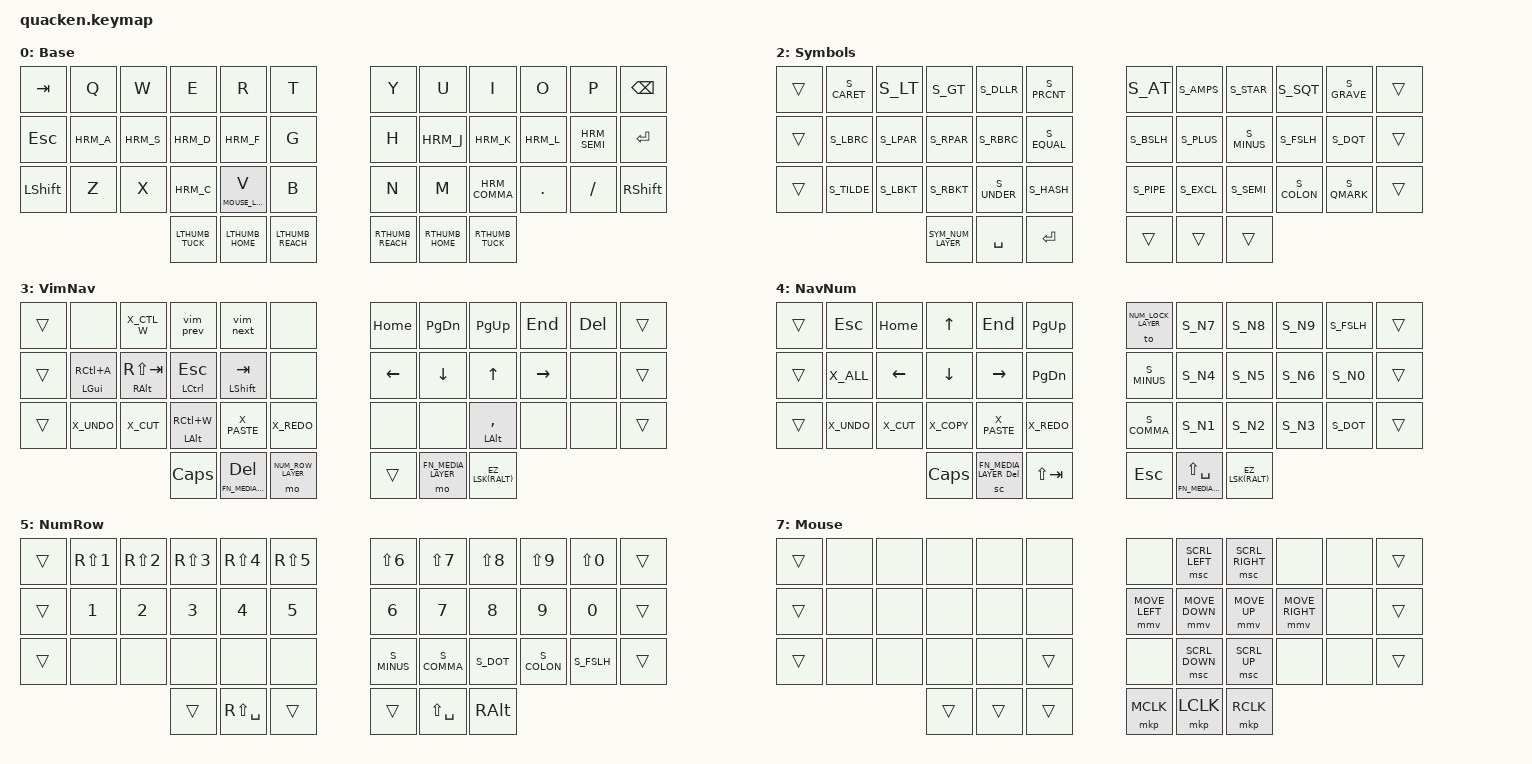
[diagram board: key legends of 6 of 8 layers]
// Selenium keymap:
// https://github.com/OneDeadKey/selenium

#ifndef CI_IGNORE_USER_SETTINGS
  #include "settings.h"   // user settings, ignored by CI tests
#endif

#include "aliases.h"      // symbols, actions, non-ASCII chars
#include "mappings.dtsi"  // key mapping helpers and macros
#include "hold_taps.dtsi" // thumb keys and homerow mods
#undef REACH_TAP
#define REACH_TAP TAB

/ {
  keymap {
    compatible = "zmk,keymap";

    // 0. Base layer -- keep the QWERTY key codes to use your OS keyboard layout
    //               -- the Space Cadet layer-tap on the right can be replaced by an AltGr/Enter mod-tap
    //               -- adjust the homerow mods with the #define statements above
    base_layer: base_layer {
      display-name = "Base";
      bindings = <
        &kp TAB    &kp Q  &kp W  &kp E  &kp R  &kp T        &kp Y  &kp U  &kp I     &kp O   &kp P      &kp BACKSPACE
        &kp ESCAPE HRM_A  HRM_S  HRM_D  HRM_F  &kp G        &kp H  HRM_J  HRM_K     HRM_L   HRM_SEMI   &kp ENTER
        &kp LSHIFT &kp Z  &kp X  HRM_C  &lt MOUSE_LAYER V  &kp B        &kp N  &kp M  HRM_COMMA &kp DOT &kp FSLH   &kp RSHIFT
                LTHUMB_TUCK  LTHUMB_HOME  LTHUMB_REACH    RTHUMB_REACH  RTHUMB_HOME  RTHUMB_TUCK
      >;
    };

    // 1. NumLock layer -- NavNum layer that stays on until deactivated without holding key
    num_lock_layer: num_lock_layer {
      display-name = "NumLock";
      bindings = <
        &trans  &kp ESC  &kp HOME &kp UP   &kp END   &kp PG_UP    &to BASE_LAYER S_N7  S_N8  S_N9  S_FSLH  &trans
        &trans  S_EQUAL  &kp LEFT &kp DOWN &kp RIGHT &kp PG_DN    S_MINUS        S_N4  S_N5  S_N6  S_N0    &trans
        &trans  S_MONEY  S_COLON  S_STAR   S_PLUS    S_PRCNT      S_COMMA        S_N1  S_N2  S_N3  S_DOT   &trans
                &trans  &sc NAV_NUM_LAYER BACKSPACE  &kp (TAB)    &trans  &lt NAV_NUM_LAYER LS(SPACE)  &EZ_SL(SYMBOLS_LAYER)
      >;
    };

    // 2. Symbols layer -- with Ergo-L, basically just an AltGr layer with custom thumb keys
    //                  -- can be redefined for non-AltGr layouts such as QWERTY-ANSI
    symbols_layer: symbols_layer {
      display-name = "Symbols";
      bindings = <
        &trans  S_CARET S_LT    S_GT    S_DLLR  S_PRCNT       S_AT    S_AMPS  S_STAR  S_SQT   S_GRAVE  &trans
        &trans  S_LBRC  S_LPAR  S_RPAR  S_RBRC  S_EQUAL       S_BSLH  S_PLUS  S_MINUS S_FSLH  S_DQT    &trans
        &trans  S_TILDE S_LBKT  S_RBKT  S_UNDER S_HASH        S_PIPE  S_EXCL  S_SEMI  S_COLON S_QMARK  &trans
                    SYM_NUM_LAYER  &kp SPACE  &kp ENTER       &trans  &trans  &trans
      >;
    };

    // 3. VimNav layer -- HJKL arrow cluster on the right hand
    //                 -- best used along with the NumRow layer
    //                 -- keyboard shortcuts on the left hand are adjusted to the OS layout (Ergo-L here)
    vim_nav_layer: vim_nav_layer {
      display-name = "VimNav";
      bindings = <
        &trans  &none    X_CTL_W  &vim_prev &vim_next &none        &kp HOME &kp PG_DN &kp PG_UP &kp END   &kp DEL &trans
        &trans  &hrm LGUI RC(A)  &hrm RALT RS(TAB)  &hrm LCTL ESC  &hrm LSHIFT TAB  &none        &kp LEFT &kp DOWN  &kp UP    &kp RIGHT &none   &trans
        &trans  X_UNDO   X_CUT    &hrm LALT RC(W)  X_PASTE   X_REDO       &none    &none     &hrm LALT COMMA  &none     &none   &trans
          &kp CAPS  &lt FN_MEDIA_LAYER DEL  &mo NUM_ROW_LAYER    &trans  &mo FN_MEDIA_LAYER  &EZ_LSK(RALT)
      >;
    };

    // 4. NavNum layer -- inverted T arrow cluster on the left hand, numpad on the right hand
    //                 -- can be the only extra layer you need if you're not too picky with number+symbols n-grams
    //                 -- keyboard shortcuts on the left hand are adjusted to the OS layout (Ergo-L here)
    nav_num_layer: nav_num_layer {
      display-name = "NavNum";
      bindings = <
        &trans  &kp ESC  &kp HOME &kp UP   &kp END   &kp PG_UP    &to NUM_LOCK_LAYER S_N7  S_N8  S_N9  S_FSLH  &trans
        &trans  X_ALL    &kp LEFT &kp DOWN &kp RIGHT &kp PG_DN    S_MINUS            S_N4  S_N5  S_N6  S_N0    &trans
        &trans  X_UNDO   X_CUT    X_COPY   X_PASTE   X_REDO       S_COMMA            S_N1  S_N2  S_N3  S_DOT   &trans
                 &kp CAPS  &sc FN_MEDIA_LAYER DEL  &kp LS(TAB)    &kp ESCAPE  &lt FN_MEDIA_LAYER LS(SPACE)  &EZ_LSK(RALT)
      >;
    };

    // 5. NumRow layer -- bring the numbers to the homerow, keep shift+numbers for shortcuts and symbols
    //                 -- space becomes shift+space, which is a no-break space with some OS layouts (e.g. Ergo-L)
    //                 -- best used along with the VimNav layer
    num_row_layer: num_row_layer {
      display-name = "NumRow";
      bindings = <
        &trans  &kp RS(N1) &kp RS(N2) &kp RS(N3) &kp RS(N4) &kp RS(N5)       &kp LS(N6) &kp LS(N7) &kp LS(N8) &kp LS(N9) &kp LS(N0) &trans
        &trans  &kp N1     &kp N2     &kp N3     &kp N4     &kp N5           &kp N6     &kp N7     &kp N8     &kp N9     &kp N0     &trans
        &trans  &none      &none      &none      &none      &none            S_MINUS    S_COMMA    S_DOT      S_COLON    S_FSLH     &trans
                                      &trans  &kp RS(SPACE) &trans           &trans  &kp LS(SPACE) &kp RALT
      >;
    };

    // 6. FnMedia layer -- F1..12 pad on the left hand, HRM on the right hand
    //                  -- reset and bootloader reset on difficult thumb keys
    //                  -- could be completed with other rare keys
    fn_media_layer: fn_media_layer {
      display-name = "FnMedia";
      bindings = <
        &trans  &kp F1  &kp F2  &kp F3  &kp F4  &none         &none  &kp C_PREV  &kp C_VOL_UP  &kp C_BRI_UP   &kp SLCK      &trans
        &trans  &kp F5  &kp F6  &kp F7  &kp F8  &none         &none  H_J C_PP    H_K C_MUTE    H_L C_AL_LOCK  H_SEMI PSCRN  &trans
        &trans  &kp F9  &kp F10 &kp F11 &kp F12 &none         &none  &kp C_NEXT  &kp C_VOL_DN  &kp C_BRI_DN   &kp INS       &trans
                                &trans  &trans  &bootloader   &sys_reset  &trans  &studio_unlock
      >;
    };

    // 7. Mouse layer -- held from the base layer's B key
    //                -- mouse movement on HJKL, scroll above/below, clicks on the right thumb keys
    mouse_layer: mouse_layer {
      display-name = "Mouse";
      bindings = <
        &trans  &none  &none  &none  &none  &none        &none            &msc SCRL_LEFT  &msc SCRL_RIGHT  &none            &none   &trans
        &trans  &none  &none  &none  &none  &none        &mmv MOVE_LEFT   &mmv MOVE_DOWN  &mmv MOVE_UP     &mmv MOVE_RIGHT  &none   &trans
        &trans  &none  &none  &none  &none  &trans       &none            &msc SCRL_DOWN  &msc SCRL_UP     &none            &none   &trans
                              &trans  &trans  &trans      &mkp MCLK  &mkp LCLK  &mkp RCLK
      >;
    };
  };
};

// Emulated layouts (experimental!)
#ifdef KB_EMULATION_DVORAK
  #include "emulations/dvorak.dtsi"
#elif defined KB_EMULATION_ERGOL
  #include "emulations/ergol.dtsi"
#elif defined KB_EMULATION_QWERTY_LAFAYETTE
  #include "emulations/qwerty_lafayette.dtsi"

// Some layouts require extra layers to fit on the Quacken.
#elif defined KB_LAYOUT_AZERTY
  #include "extra_layers/azerty.dtsi"
#elif defined KB_LAYOUT_BEPO
  #include "extra_layers/bepo.dtsi"
#elif defined KB_LAYOUT_ERGOL && defined HUMMINGBIRD
  #include "extra_layers/ergol_hummingbird.dtsi"
#endif
